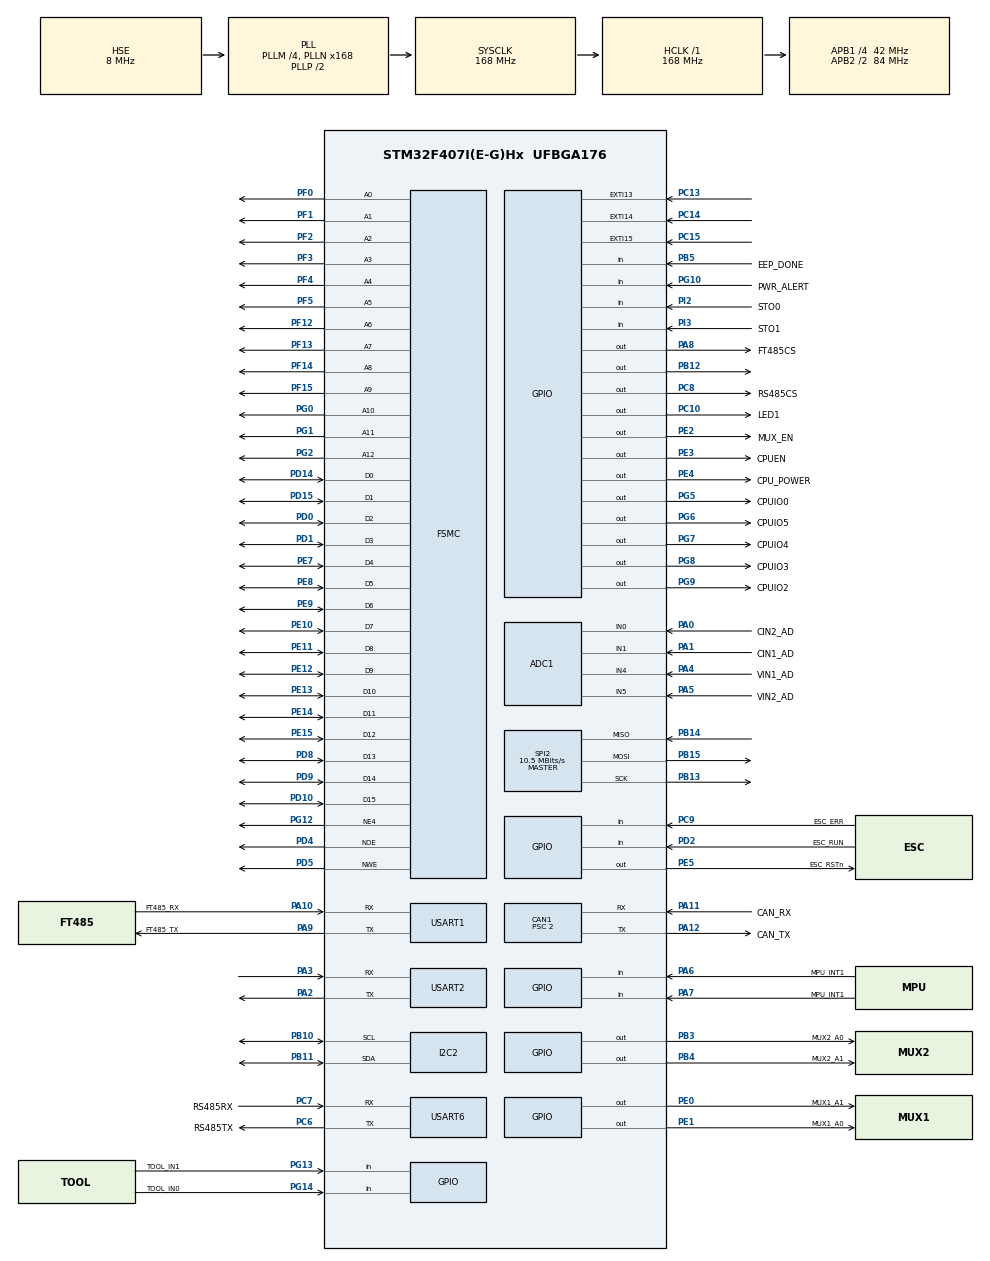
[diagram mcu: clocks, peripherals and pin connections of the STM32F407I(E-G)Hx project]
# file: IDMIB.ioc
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ADC1.Channel-0\#ChannelRegularConversion=ADC_CHANNEL_0
ADC1.Channel-1\#ChannelRegularConversion=ADC_CHANNEL_1
ADC1.Channel-2\#ChannelRegularConversion=ADC_CHANNEL_4
ADC1.Channel-3\#ChannelRegularConversion=ADC_CHANNEL_5
ADC1.Channel-4\#ChannelRegularConversion=ADC_CHANNEL_TEMPSENSOR
ADC1.ClockPrescaler=ADC_CLOCK_SYNC_PCLK_DIV8
ADC1.ContinuousConvMode=ENABLE
ADC1.DMAContinuousRequests=ENABLE
ADC1.NbrOfConversion=5
ADC1.NbrOfConversionFlag=1
ADC1.Rank-0\#ChannelRegularConversion=1
ADC1.Rank-1\#ChannelRegularConversion=2
ADC1.Rank-2\#ChannelRegularConversion=3
ADC1.Rank-3\#ChannelRegularConversion=4
ADC1.Rank-4\#ChannelRegularConversion=5
ADC1.SamplingTime-0\#ChannelRegularConversion=ADC_SAMPLETIME_3CYCLES
ADC1.SamplingTime-1\#ChannelRegularConversion=ADC_SAMPLETIME_3CYCLES
ADC1.SamplingTime-2\#ChannelRegularConversion=ADC_SAMPLETIME_3CYCLES
ADC1.SamplingTime-3\#ChannelRegularConversion=ADC_SAMPLETIME_3CYCLES
ADC1.SamplingTime-4\#ChannelRegularConversion=ADC_SAMPLETIME_144CYCLES
ADC1.ScanConvMode=ENABLE
ADC1.master=1
CAN1.BS1=CAN_BS1_15TQ
CAN1.BS2=CAN_BS2_5TQ
CAN1.CalculateBaudRate=1000000
CAN1.CalculateTimeBit=1000
CAN1.CalculateTimeQuantum=47.61904761904762
CAN1.Prescaler=2
Dma.ADC1.3.Direction=DMA_PERIPH_TO_MEMORY
Dma.ADC1.3.FIFOMode=DMA_FIFOMODE_DISABLE
Dma.ADC1.3.Instance=DMA2_Stream0
Dma.ADC1.3.MemDataAlignment=DMA_MDATAALIGN_WORD
Dma.ADC1.3.MemInc=DMA_MINC_ENABLE
Dma.ADC1.3.Mode=DMA_CIRCULAR
Dma.ADC1.3.PeriphDataAlignment=DMA_PDATAALIGN_WORD
Dma.ADC1.3.PeriphInc=DMA_PINC_DISABLE
Dma.ADC1.3.Priority=DMA_PRIORITY_LOW
Dma.Request0=USART1_RX
Dma.Request1=USART2_RX
Dma.Request2=USART6_RX
Dma.Request3=ADC1
Dma.Request4=SPI2_RX
Dma.Request5=SPI2_TX
Dma.SPI2_RX.4.Direction=DMA_PERIPH_TO_MEMORY
Dma.SPI2_RX.4.FIFOMode=DMA_FIFOMODE_DISABLE
Dma.SPI2_RX.4.Instance=DMA1_Stream3
Dma.SPI2_RX.4.MemDataAlignment=DMA_MDATAALIGN_BYTE
Dma.SPI2_RX.4.MemInc=DMA_MINC_ENABLE
Dma.SPI2_RX.4.Mode=DMA_NORMAL
Dma.SPI2_RX.4.PeriphDataAlignment=DMA_PDATAALIGN_BYTE
Dma.SPI2_RX.4.PeriphInc=DMA_PINC_DISABLE
Dma.SPI2_RX.4.Priority=DMA_PRIORITY_LOW
Dma.SPI2_TX.5.Direction=DMA_MEMORY_TO_PERIPH
Dma.SPI2_TX.5.FIFOMode=DMA_FIFOMODE_DISABLE
Dma.SPI2_TX.5.Instance=DMA1_Stream4
Dma.SPI2_TX.5.MemDataAlignment=DMA_MDATAALIGN_BYTE
Dma.SPI2_TX.5.MemInc=DMA_MINC_ENABLE
Dma.SPI2_TX.5.Mode=DMA_NORMAL
Dma.SPI2_TX.5.PeriphDataAlignment=DMA_PDATAALIGN_BYTE
Dma.SPI2_TX.5.PeriphInc=DMA_PINC_DISABLE
Dma.SPI2_TX.5.Priority=DMA_PRIORITY_LOW
Dma.USART1_RX.0.Direction=DMA_PERIPH_TO_MEMORY
Dma.USART1_RX.0.FIFOMode=DMA_FIFOMODE_DISABLE
Dma.USART1_RX.0.Instance=DMA2_Stream2
Dma.USART1_RX.0.MemDataAlignment=DMA_MDATAALIGN_BYTE
Dma.USART1_RX.0.MemInc=DMA_MINC_ENABLE
Dma.USART1_RX.0.Mode=DMA_NORMAL
Dma.USART1_RX.0.PeriphDataAlignment=DMA_PDATAALIGN_BYTE
Dma.USART1_RX.0.PeriphInc=DMA_PINC_DISABLE
Dma.USART1_RX.0.Priority=DMA_PRIORITY_LOW
Dma.USART2_RX.1.Direction=DMA_PERIPH_TO_MEMORY
Dma.USART2_RX.1.FIFOMode=DMA_FIFOMODE_DISABLE
Dma.USART2_RX.1.Instance=DMA1_Stream5
Dma.USART2_RX.1.MemDataAlignment=DMA_MDATAALIGN_BYTE
Dma.USART2_RX.1.MemInc=DMA_MINC_ENABLE
Dma.USART2_RX.1.Mode=DMA_NORMAL
Dma.USART2_RX.1.PeriphDataAlignment=DMA_PDATAALIGN_BYTE
Dma.USART2_RX.1.PeriphInc=DMA_PINC_DISABLE
Dma.USART2_RX.1.Priority=DMA_PRIORITY_LOW
Dma.USART6_RX.2.Direction=DMA_PERIPH_TO_MEMORY
Dma.USART6_RX.2.FIFOMode=DMA_FIFOMODE_DISABLE
Dma.USART6_RX.2.Instance=DMA2_Stream1
Dma.USART6_RX.2.MemDataAlignment=DMA_MDATAALIGN_BYTE
Dma.USART6_RX.2.MemInc=DMA_MINC_ENABLE
Dma.USART6_RX.2.Mode=DMA_NORMAL
Dma.USART6_RX.2.PeriphDataAlignment=DMA_PDATAALIGN_BYTE
Dma.USART6_RX.2.PeriphInc=DMA_PINC_DISABLE
Dma.USART6_RX.2.Priority=DMA_PRIORITY_LOW
FSMC.AddressSetupTime1=4
FSMC.BusTurnAroundDuration1=1
FSMC.DataSetupTime1=60
FSMC.WriteOperation1=FSMC_WRITE_OPERATION_ENABLE
Mcu.Family=STM32F4
Mcu.Name=STM32F407I(E-G)Hx
Mcu.Package=UFBGA176
NVIC.CAN1_RX0_IRQn=true\:0\:0\:false\:false\:true\:true\:true\:true
NVIC.CAN1_RX1_IRQn=true\:0\:0\:false\:false\:true\:true\:true\:true
NVIC.DMA1_Stream3_IRQn=true\:0\:0\:false\:false\:true\:false\:true\:true
NVIC.DMA1_Stream4_IRQn=true\:0\:0\:false\:false\:true\:false\:true\:true
NVIC.DMA1_Stream5_IRQn=true\:0\:0\:false\:false\:true\:false\:true\:true
NVIC.DMA2_Stream0_IRQn=true\:0\:0\:false\:false\:true\:false\:true\:true
NVIC.DMA2_Stream1_IRQn=true\:0\:0\:false\:false\:true\:false\:true\:true
NVIC.DMA2_Stream2_IRQn=true\:0\:0\:false\:false\:true\:false\:true\:true
NVIC.EXTI15_10_IRQn=true\:0\:0\:false\:false\:true\:true\:true\:true
NVIC.I2C2_ER_IRQn=true\:0\:0\:false\:false\:true\:true\:true\:true
NVIC.I2C2_EV_IRQn=true\:0\:0\:false\:false\:true\:true\:true\:true
NVIC.PriorityGroup=NVIC_PRIORITYGROUP_2
NVIC.SPI2_IRQn=true\:1\:0\:true\:false\:true\:true\:true\:true
NVIC.TIM1_BRK_TIM9_IRQn=true\:0\:0\:false\:false\:true\:true\:true\:true
NVIC.TIM4_IRQn=true\:0\:0\:false\:false\:true\:true\:true\:true
NVIC.TIM6_DAC_IRQn=true\:1\:0\:true\:false\:true\:true\:true\:true
NVIC.USART1_IRQn=true\:0\:0\:false\:false\:true\:true\:true\:true
NVIC.USART2_IRQn=true\:0\:0\:false\:false\:true\:true\:true\:true
NVIC.USART6_IRQn=true\:1\:0\:true\:false\:true\:true\:true\:true
PA0-WKUP.GPIO_Label=CIN2_AD
PA0-WKUP.Signal=ADCx_IN0
PA1.GPIO_Label=CIN1_AD
PA1.Signal=ADCx_IN1
PA10.GPIO_Label=FT485_RX
PA10.Mode=Asynchronous
PA10.Signal=USART1_RX
PA11.GPIO_Label=CAN_RX
PA11.Mode=CAN_Activate
PA11.Signal=CAN1_RX
PA12.GPIO_Label=CAN_TX
PA12.Mode=CAN_Activate
PA12.Signal=CAN1_TX
PA13.Mode=Serial_Wire
PA13.Signal=SYS_JTMS-SWDIO
PA14.Mode=Serial_Wire
PA14.Signal=SYS_JTCK-SWCLK
PA2.Mode=Asynchronous
PA2.Signal=USART2_TX
PA3.Mode=Asynchronous
PA3.Signal=USART2_RX
PA4.GPIO_Label=VIN1_AD
PA4.Signal=ADCx_IN4
PA5.GPIO_Label=VIN2_AD
PA5.Signal=ADCx_IN5
PA6.GPIO_Label=MPU_INT1
PA6.Signal=GPIO_Input
PA7.GPIO_Label=MPU_INT1
PA7.Signal=GPIO_Input
PA8.GPIO_Label=FT485CS
PA8.Signal=GPIO_Output
PA9.GPIO_Label=FT485_TX
PA9.Mode=Asynchronous
PA9.Signal=USART1_TX
PB10.Mode=I2C
PB10.Signal=I2C2_SCL
PB11.Mode=I2C
PB11.Signal=I2C2_SDA
PB12.Signal=GPIO_Output
PB13.Mode=Full_Duplex_Master
PB13.Signal=SPI2_SCK
PB14.Mode=Full_Duplex_Master
PB14.Signal=SPI2_MISO
PB15.Mode=Full_Duplex_Master
PB15.Signal=SPI2_MOSI
PB3.GPIO_Label=MUX2_A0
PB3.Signal=GPIO_Output
PB4.GPIO_Label=MUX2_A1
PB4.Signal=GPIO_Output
PB5.GPIO_Label=EEP_DONE
PB5.Signal=GPIO_Input
PC10.GPIO_Label=LED1
PC10.Signal=GPIO_Output
PC13-ANTI_TAMP.Signal=GPXTI13
PC14-OSC32_IN.Signal=GPXTI14
PC15-OSC32_OUT.Signal=GPXTI15
PC6.GPIO_Label=RS485TX
PC6.Mode=Asynchronous
PC6.Signal=USART6_TX
PC7.GPIO_Label=RS485RX
PC7.Mode=Asynchronous
PC7.Signal=USART6_RX
PC8.GPIO_Label=RS485CS
PC8.Signal=GPIO_Output
PC9.GPIO_Label=ESC_ERR
PC9.Signal=GPIO_Input
PD0.Signal=FSMC_D2_DA2
PD1.Signal=FSMC_D3_DA3
PD10.Signal=FSMC_D15_DA15
PD14.Signal=FSMC_D0_DA0
PD15.Signal=FSMC_D1_DA1
PD2.GPIO_Label=ESC_RUN
PD2.Signal=GPIO_Input
PD4.Signal=FSMC_NOE
PD5.Signal=FSMC_NWE
PD8.Signal=FSMC_D13_DA13
PD9.Signal=FSMC_D14_DA14
PE0.GPIO_Label=MUX1_A1
PE0.Signal=GPIO_Output
PE1.GPIO_Label=MUX1_A0
PE1.Signal=GPIO_Output
PE10.Signal=FSMC_D7_DA7
PE11.Signal=FSMC_D8_DA8
PE12.Signal=FSMC_D9_DA9
PE13.Signal=FSMC_D10_DA10
PE14.Signal=FSMC_D11_DA11
PE15.Signal=FSMC_D12_DA12
PE2.GPIO_Label=MUX_EN
PE2.Signal=GPIO_Output
PE3.GPIO_Label=CPUEN
PE3.GPIO_ModeDefaultOutputPP=GPIO_MODE_OUTPUT_PP
PE3.GPIO_PuPd=GPIO_NOPULL
PE3.PinState=GPIO_PIN_SET
PE3.Signal=GPIO_Output
PE4.GPIO_Label=CPU_POWER
PE4.Signal=GPIO_Output
PE5.GPIO_Label=ESC_RSTn
PE5.Signal=GPIO_Output
PE7.Signal=FSMC_D4_DA4
PE8.Signal=FSMC_D5_DA5
PE9.Signal=FSMC_D6_DA6
PF0.Signal=FSMC_A0
PF1.Signal=FSMC_A1
PF12.Signal=FSMC_A6
PF13.Signal=FSMC_A7
PF14.Signal=FSMC_A8
PF15.Signal=FSMC_A9
PF2.Signal=FSMC_A2
PF3.Signal=FSMC_A3
PF4.Signal=FSMC_A4
PF5.Signal=FSMC_A5
PG0.Signal=FSMC_A10
PG1.Signal=FSMC_A11
PG10.GPIO_Label=PWR_ALERT
PG10.Signal=GPIO_Input
PG12.Mode=NorPsramChipSelect4_1
PG12.Signal=FSMC_NE4
PG13.GPIO_Label=TOOL_IN1
PG13.Signal=GPIO_Input
PG14.GPIO_Label=TOOL_IN0
PG14.Signal=GPIO_Input
PG2.Signal=FSMC_A12
PG5.GPIO_Label=CPUIO0
PG5.Signal=GPIO_Output
PG6.GPIO_Label=CPUIO5
PG6.Signal=GPIO_Output
PG7.GPIO_Label=CPUIO4
PG7.Signal=GPIO_Output
PG8.GPIO_Label=CPUIO3
PG8.Signal=GPIO_Output
PG9.GPIO_Label=CPUIO2
PG9.Signal=GPIO_Output
PH0-OSC_IN.Mode=HSE-External-Oscillator
PH0-OSC_IN.Signal=RCC_OSC_IN
PH1-OSC_OUT.Mode=HSE-External-Oscillator
PH1-OSC_OUT.Signal=RCC_OSC_OUT
PI2.GPIO_Label=STO0
PI2.Signal=GPIO_Input
PI3.GPIO_Label=STO1
PI3.Signal=GPIO_Input
ProjectManager.HeapSize=0x1000
ProjectManager.StackSize=0x400
ProjectManager.TargetToolchain=MDK-ARM V5.32
RCC.48MHZClocksFreq_Value=84000000
RCC.AHBFreq_Value=168000000
RCC.APB1CLKDivider=RCC_HCLK_DIV4
RCC.APB1Freq_Value=42000000
RCC.APB1TimFreq_Value=84000000
RCC.APB2CLKDivider=RCC_HCLK_DIV2
RCC.APB2Freq_Value=84000000
RCC.APB2TimFreq_Value=168000000
RCC.CortexFreq_Value=168000000
RCC.HCLKFreq_Value=168000000
RCC.HSE_VALUE=8000000
RCC.HSI_VALUE=16000000
RCC.LSE_VALUE=32768
RCC.PLLM=4
RCC.PLLN=168
RCC.PLLSourceVirtual=RCC_PLLSOURCE_HSE
RCC.SYSCLKFreq_VALUE=168000000
RCC.SYSCLKSource=RCC_SYSCLKSOURCE_PLLCLK
RCC.VCOOutputFreq_Value=336000000
SH.ADCx_IN0.0=ADC1_IN0,IN0
SH.ADCx_IN1.0=ADC1_IN1,IN1
SH.ADCx_IN4.0=ADC1_IN4,IN4
SH.ADCx_IN5.0=ADC1_IN5,IN5
SH.FSMC_A0.0=FSMC_A0,13b-a1
SH.FSMC_A1.0=FSMC_A1,13b-a1
SH.FSMC_A10.0=FSMC_A10,13b-a1
SH.FSMC_A11.0=FSMC_A11,13b-a1
SH.FSMC_A12.0=FSMC_A12,13b-a1
SH.FSMC_A2.0=FSMC_A2,13b-a1
SH.FSMC_A3.0=FSMC_A3,13b-a1
SH.FSMC_A4.0=FSMC_A4,13b-a1
SH.FSMC_A5.0=FSMC_A5,13b-a1
SH.FSMC_A6.0=FSMC_A6,13b-a1
SH.FSMC_A7.0=FSMC_A7,13b-a1
SH.FSMC_A8.0=FSMC_A8,13b-a1
SH.FSMC_A9.0=FSMC_A9,13b-a1
SH.FSMC_D0_DA0.0=FSMC_D0,16b-d1
SH.FSMC_D10_DA10.0=FSMC_D10,16b-d1
SH.FSMC_D11_DA11.0=FSMC_D11,16b-d1
SH.FSMC_D12_DA12.0=FSMC_D12,16b-d1
SH.FSMC_D13_DA13.0=FSMC_D13,16b-d1
SH.FSMC_D14_DA14.0=FSMC_D14,16b-d1
SH.FSMC_D15_DA15.0=FSMC_D15,16b-d1
SH.FSMC_D1_DA1.0=FSMC_D1,16b-d1
SH.FSMC_D2_DA2.0=FSMC_D2,16b-d1
SH.FSMC_D3_DA3.0=FSMC_D3,16b-d1
SH.FSMC_D4_DA4.0=FSMC_D4,16b-d1
SH.FSMC_D5_DA5.0=FSMC_D5,16b-d1
SH.FSMC_D6_DA6.0=FSMC_D6,16b-d1
SH.FSMC_D7_DA7.0=FSMC_D7,16b-d1
SH.FSMC_D8_DA8.0=FSMC_D8,16b-d1
SH.FSMC_D9_DA9.0=FSMC_D9,16b-d1
SH.FSMC_NOE.0=FSMC_NOE,Sram1
SH.FSMC_NWE.0=FSMC_NWE,Sram1
SPI2.BaudRatePrescaler=SPI_BAUDRATEPRESCALER_4
SPI2.CRCCalculation=SPI_CRCCALCULATION_DISABLE
SPI2.CalculateBaudRate=10.5 MBits/s
SPI2.Direction=SPI_DIRECTION_2LINES
SPI2.Mode=SPI_MODE_MASTER
SPI2.VirtualType=VM_MASTER
TIM2.Period=20-1
TIM2.Prescaler=840-1
TIM3.Prescaler=84-1
TIM4.Period=1000-1
TIM4.Prescaler=84-1
TIM6.Prescaler=84-1
TIM7.Period=1000-1
TIM7.Prescaler=84-1
TIM9.Period=2000-1
TIM9.Prescaler=84-1
USART1.VirtualMode=VM_ASYNC
USART2.VirtualMode=VM_ASYNC
USART6.VirtualMode=VM_ASYNC
VP_ADC1_TempSens_Input.Mode=IN-TempSens
VP_TIM2_VS_ClockSourceINT.Mode=Internal
VP_TIM3_VS_ClockSourceINT.Mode=Internal
VP_TIM4_VS_ClockSourceINT.Mode=Internal
VP_TIM6_VS_ClockSourceINT.Mode=Enable_Timer
VP_TIM7_VS_ClockSourceINT.Mode=Enable_Timer
VP_TIM9_VS_ClockSourceINT.Mode=Internal
board=custom

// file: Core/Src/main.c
/* USER CODE BEGIN Header */
/**
  ******************************************************************************
  * @file           : main.c
  * @brief          : Main program body
  ******************************************************************************
  * @attention
  *
  * <h2><center>&copy; Copyright (c) 2020 STMicroelectronics.
  * All rights reserved.</center></h2>
  *
  * This software component is licensed by ST under BSD 3-Clause license,
  * the "License"; You may not use this file except in compliance with the
  * License. You may obtain a copy of the License at:
  *                        opensource.org/licenses/BSD-3-Clause
  *
  ******************************************************************************
  */
/* USER CODE END Header */
#include "main.h"
#include "adc.h"
#include "can.h"
#include "dma.h"
#include "i2c.h"
#include "spi.h"
#include "tim.h"
#include "usart.h"
#include "gpio.h"
#include "fsmc.h"

/* USER CODE BEGIN Includes */
#include "samplehw.h"
#include "ecatappl.h"
/* USER CODE END Includes */

/* USER CODE BEGIN PTD */
//void Test(void);
/* USER CODE END PTD */

void SystemClock_Config(void);
/* USER CODE BEGIN PFP */
void Test(void);
/* USER CODE END PFP */

int main(void)
{

  /* MCU Configuration--------------------------------------------------------*/

  /* Reset of all peripherals, Initializes the Flash interface and the Systick. */
  HAL_Init();

  /* Configure the system clock */
  SystemClock_Config();

  /* Initialize all configured peripherals */
  MX_GPIO_Init();
  MX_DMA_Init();
  MX_ADC1_Init();
  MX_USART1_UART_Init();
  MX_USART2_UART_Init();
  MX_CAN1_Init();
  MX_I2C2_Init();
  MX_SPI2_Init();
  MX_USART6_UART_Init();
  MX_TIM4_Init();
  MX_TIM6_Init();
  MX_TIM2_Init();
  MX_TIM3_Init();
  MX_FSMC_Init();
  MX_TIM7_Init();
  MX_TIM9_Init();
  /* USER CODE BEGIN 2 */
	/* Keep initializing bsp until success */
	while (BSP_Global_Init())
	{
		printf("BSP init failed ... \r\n");
		BSP_LED1_Toggle;
		Delay_ms(500);
	}

	/* Keep checking encryption until success */
//	while (BSP_Encrypt_Chip_Check())
//	{
//		printf("Encryption check failed ... \r\n");
//		BSP_LED1_Toggle;
//		Delay_ms(500);
//	}

	/* Bootloader related*/
//	if (firmware_update)
//	{
//		printf("To update firmware ... \r\n");
//		// To do
//	}

	/* Keep searching for IMU until found */
	while (Find_IMU())
	{
		printf("IMU not found ... \r\n");
		BSP_LED1_Toggle;
		Delay_ms(500);
	}

	/* Base Init*/
	//Flash_Mem_Read(base_state, BASE_STATE_BUF_SIZE*2, FLASH_START_ADDR_SYSTEM_STATE);
	//Put everything to default safe state

//	BSP_Clock_Register(&runtime_clock);

	printf("\r\nReady to go ... \r\n");
	//Test();

  /* USER CODE END 2 */

  /* Infinite loop */
  while (1)
  {

    /* USER CODE BEGIN 3 */
		House_Keeping();

		//CMD_Processing();

//	  HAL_Delay(5000);
	  //BSP_LED1_Toggle;
//	  BSP_CAN_Test();
//	  Get_Tool_Temp();
//	  BSP_I2C_test();
//	  BSP_Get_Chip_ID();
//	  BSP_Output_PWR_Test();
//	  BSP_Output_DO_Test();
	  //Test();

#if (ETHERCAT_SLAVE_STACK_ENABLE)
		HW_IntrDequeue();
		MainLoop();
#endif

  }
  /* USER CODE END 3 */
}

void SystemClock_Config(void)
{
  RCC_OscInitTypeDef RCC_OscInitStruct = {0};
  RCC_ClkInitTypeDef RCC_ClkInitStruct = {0};

  /** Configure the main internal regulator output voltage
  */
  __HAL_RCC_PWR_CLK_ENABLE();
  __HAL_PWR_VOLTAGESCALING_CONFIG(PWR_REGULATOR_VOLTAGE_SCALE1);

  /** Initializes the RCC Oscillators according to the specified parameters
  * in the RCC_OscInitTypeDef structure.
  */
  RCC_OscInitStruct.OscillatorType = RCC_OSCILLATORTYPE_HSE;
  RCC_OscInitStruct.HSEState = RCC_HSE_ON;
  RCC_OscInitStruct.PLL.PLLState = RCC_PLL_ON;
  RCC_OscInitStruct.PLL.PLLSource = RCC_PLLSOURCE_HSE;
  RCC_OscInitStruct.PLL.PLLM = 4;
  RCC_OscInitStruct.PLL.PLLN = 168;
  RCC_OscInitStruct.PLL.PLLP = RCC_PLLP_DIV2;
  RCC_OscInitStruct.PLL.PLLQ = 4;
  if (HAL_RCC_OscConfig(&RCC_OscInitStruct) != HAL_OK)
  {
    Error_Handler();
  }

  /** Initializes the CPU, AHB and APB buses clocks
  */
  RCC_ClkInitStruct.ClockType = RCC_CLOCKTYPE_HCLK|RCC_CLOCKTYPE_SYSCLK
                              |RCC_CLOCKTYPE_PCLK1|RCC_CLOCKTYPE_PCLK2;
  RCC_ClkInitStruct.SYSCLKSource = RCC_SYSCLKSOURCE_PLLCLK;
  RCC_ClkInitStruct.AHBCLKDivider = RCC_SYSCLK_DIV1;
  RCC_ClkInitStruct.APB1CLKDivider = RCC_HCLK_DIV4;
  RCC_ClkInitStruct.APB2CLKDivider = RCC_HCLK_DIV2;

  if (HAL_RCC_ClockConfig(&RCC_ClkInitStruct, FLASH_LATENCY_5) != HAL_OK)
  {
    Error_Handler();
  }
}

/* USER CODE BEGIN 4 */

void Test(void)   //���Ը��ֹ���
{
	BSP_LED1_ON;  //����LED

	/*CPU ID Test*/
	BSP_Get_Chip_ID();
	printf("Chip ID: %X-%X-%X\r\n",CPU_ID[0],CPU_ID[1],CPU_ID[2]);
	printf("Flash Size: %dK \r\n\r\n", *(__IO uint16_t *)(0x1FFF7A22));
	HAL_Delay(1000);

	/*Debug Uart Test*/
	printf("Smokie BSP  : STM32F405RGT6_v1.0.1\r\n");
	printf("Date        : 07-12-2020\r\n");
	printf("COPYRIGHT 2020 Smokie Robotics, Inc\r\n\r\n");
	HAL_Delay(1000);

	/*��Դ�������������??*/
	DIO_Power_On();
	DO_PWR_Config(PWR_24);
//	DO0_Config(DO_Port_Active, DO_Port_Type_NPN);

////set DO0 to GND
//	BSP_CPUIO2_OFF;
//	BSP_CPUIO3_ON;
//
	DO1_Config(DO_Port_Active, DO_Port_Type_PP);
	DO0_Config(DO_Port_Active, DO_Port_Type_PP);
	BSP_Output_DO0(Port_ON);
	BSP_Output_DO1(Port_ON);
//	AI_Port_Config(Read_Voltage);
	AI_Port_Config(Read_Current);

//	BSP_SPST_485_EN();
	FT485_Transmit_ENABLE;

	uint8_t rs485_data[3]={0xA,0xB,0xC};

	while(1)
	{
		printf("TI0 Value: %d \r\n",Read_DI_Port(Port_TI0));
		printf("TI1 Value: %d \r\n\n",Read_DI_Port(Port_TI1));
//		printf("Ain1 Value: %ld \r\n",AI_Port_Read(Port_AI0, Read_Voltage));
//		printf("Ain2 Value: %ld \r\n",AI_Port_Read(Port_AI1, Read_Voltage));
		printf("Ain1 Value: %ld \r\n",AI_Port_Read(Port_AI0, Read_Current));
		printf("Ain2 Value: %ld \r\n\n",AI_Port_Read(Port_AI1, Read_Current));
//		HAL_UART_Transmit(&huart1, rs485_data, 3, 1000);

		printf("STO0 Value: %d \r\n", STO0_Read());
		printf("STO1 Value: %d \r\n", STO1_Read());

//		Robot_State_Printf();
		HAL_Delay(1000);
	}

}

/* USER CODE END 4 */

void Error_Handler(void)
{
}
